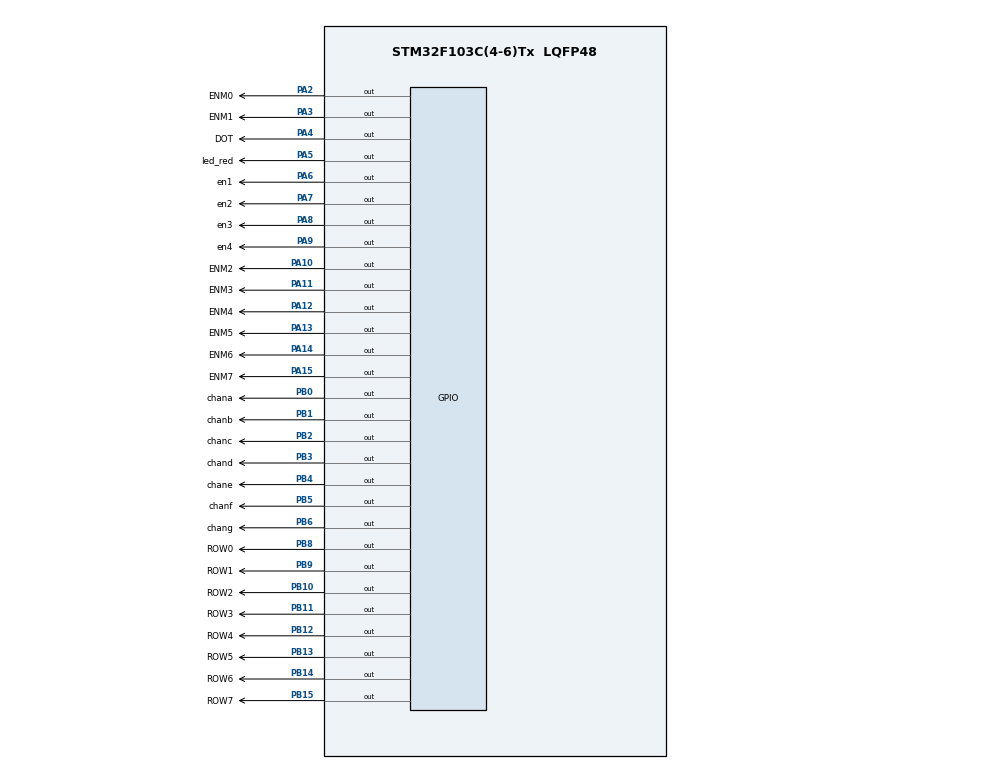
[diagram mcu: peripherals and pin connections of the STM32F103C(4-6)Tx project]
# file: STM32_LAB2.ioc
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Mcu.Family=STM32F1
Mcu.Name=STM32F103C(4-6)Tx
Mcu.Package=LQFP48
NVIC.PriorityGroup=NVIC_PRIORITYGROUP_4
NVIC.TIM2_IRQn=true\:0\:0\:false\:false\:true\:true\:true\:true
PA10.GPIO_Label=ENM2
PA10.Signal=GPIO_Output
PA11.GPIO_Label=ENM3
PA11.Signal=GPIO_Output
PA12.GPIO_Label=ENM4
PA12.Signal=GPIO_Output
PA13.GPIO_Label=ENM5
PA13.Signal=GPIO_Output
PA14.GPIO_Label=ENM6
PA14.Signal=GPIO_Output
PA15.GPIO_Label=ENM7
PA15.Signal=GPIO_Output
PA2.GPIO_Label=ENM0
PA2.Signal=GPIO_Output
PA3.GPIO_Label=ENM1
PA3.Signal=GPIO_Output
PA4.GPIO_Label=DOT
PA4.Signal=GPIO_Output
PA5.GPIO_Label=led_red
PA5.Signal=GPIO_Output
PA6.GPIO_Label=en1
PA6.Signal=GPIO_Output
PA7.GPIO_Label=en2
PA7.Signal=GPIO_Output
PA8.GPIO_Label=en3
PA8.Signal=GPIO_Output
PA9.GPIO_Label=en4
PA9.Signal=GPIO_Output
PB0.GPIO_Label=chana
PB0.Signal=GPIO_Output
PB1.GPIO_Label=chanb
PB1.Signal=GPIO_Output
PB10.GPIO_Label=ROW2
PB10.Signal=GPIO_Output
PB11.GPIO_Label=ROW3
PB11.Signal=GPIO_Output
PB12.GPIO_Label=ROW4
PB12.Signal=GPIO_Output
PB13.GPIO_Label=ROW5
PB13.Signal=GPIO_Output
PB14.GPIO_Label=ROW6
PB14.Signal=GPIO_Output
PB15.GPIO_Label=ROW7
PB15.Signal=GPIO_Output
PB2.GPIO_Label=chanc
PB2.Signal=GPIO_Output
PB3.GPIO_Label=chand
PB3.Signal=GPIO_Output
PB4.GPIO_Label=chane
PB4.Signal=GPIO_Output
PB5.GPIO_Label=chanf
PB5.Signal=GPIO_Output
PB6.GPIO_Label=chang
PB6.Signal=GPIO_Output
PB8.GPIO_Label=ROW0
PB8.Signal=GPIO_Output
PB9.GPIO_Label=ROW1
PB9.Signal=GPIO_Output
ProjectManager.HeapSize=0x200
ProjectManager.StackSize=0x400
ProjectManager.TargetToolchain=STM32CubeIDE
RCC.APB1Freq_Value=8000000
RCC.APB2Freq_Value=8000000
TIM2.Period=9
TIM2.Prescaler=7999
VP_TIM2_VS_ClockSourceINT.Mode=Internal
board=custom

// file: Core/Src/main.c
/* USER CODE BEGIN Header */
/**
  ******************************************************************************
  * @file           : main.c
  * @brief          : Main program body
  ******************************************************************************
  * @attention
  *
  * Copyright (c) 2023 STMicroelectronics.
  * All rights reserved.
  *
  * This software is licensed under terms that can be found in the LICENSE file
  * in the root directory of this software component.
  * If no LICENSE file comes with this software, it is provided AS-IS.
  *
  ******************************************************************************
  */
/* USER CODE END Header */
#include "main.h"

/* USER CODE BEGIN Includes */
#include "software_timer.h"
/* USER CODE END Includes */

TIM_HandleTypeDef htim2;

void SystemClock_Config(void);
static void MX_GPIO_Init(void);
static void MX_TIM2_Init(void);

int main(void)
{

  /* MCU Configuration--------------------------------------------------------*/

  /* Reset of all peripherals, Initializes the Flash interface and the Systick. */
  HAL_Init();

  /* Configure the system clock */
  SystemClock_Config();

  /* Initialize all configured peripherals */
  MX_GPIO_Init();
  MX_TIM2_Init();
  /* USER CODE BEGIN 2 */
  HAL_TIM_Base_Start_IT(&htim2);
  /* USER CODE END 2 */

  /* Infinite loop */
  /* USER CODE BEGIN WHILE */
  const int MAX_LED_MATRIX = 8;
  int index_led_matrix = 0;
  uint8_t matrix_buffer[8] = {0x01, 0x02, 0x03, 0x04, 0x05, 0x06, 0x07, 0x08};

  void updateLEDMatrix(int index) {
      switch (index) {
          case 0:
              // Define the pattern for displaying "A" at index 0
              matrix_buffer[0] = 0b00111100;
              matrix_buffer[1] = 0b01100110;
              matrix_buffer[2] = 0b11000011;
              matrix_buffer[3] = 0b11000011;
              matrix_buffer[4] = 0b11111111;
              matrix_buffer[5] = 0b11000011;
              matrix_buffer[6] = 0b11000011;
              matrix_buffer[7] = 0b00000000;
              break;
          // Define patterns for other indices if needed

          default:
              // Default case, clear the matrix_buffer
              for (int i = 0; i < MAX_LED_MATRIX; i++) {
                  matrix_buffer[i] = 0x00;
              }
              break;
      }
  }

  void display7SEG(int n)
   {
   	switch (n)
   	{
   	case 0 :
   		HAL_GPIO_WritePin(chana_GPIO_Port,chana_Pin, RESET);
   		HAL_GPIO_WritePin(chanb_GPIO_Port,chanb_Pin, RESET);
   		HAL_GPIO_WritePin(chanc_GPIO_Port,chanc_Pin, RESET);
   		HAL_GPIO_WritePin(chand_GPIO_Port,chand_Pin, RESET);
   		HAL_GPIO_WritePin(chane_GPIO_Port,chane_Pin, RESET);
   		HAL_GPIO_WritePin(chanf_GPIO_Port,chanf_Pin, RESET);
   		HAL_GPIO_WritePin(chang_GPIO_Port,chang_Pin, SET);
   	    break ;
   	case 1 :
   		HAL_GPIO_WritePin(chana_GPIO_Port,chana_Pin, SET);
   		HAL_GPIO_WritePin(chanb_GPIO_Port,chanb_Pin, RESET);
   		HAL_GPIO_WritePin(chanc_GPIO_Port,chanc_Pin, RESET);
   		HAL_GPIO_WritePin(chand_GPIO_Port,chand_Pin, SET);
   		HAL_GPIO_WritePin(chane_GPIO_Port,chane_Pin, SET);
   		HAL_GPIO_WritePin(chanf_GPIO_Port,chanf_Pin, SET);
   		HAL_GPIO_WritePin(chang_GPIO_Port,chang_Pin, SET);
   	    break;
   	case 2 :
   		HAL_GPIO_WritePin(chana_GPIO_Port,chana_Pin, RESET);
   		HAL_GPIO_WritePin(chanb_GPIO_Port,chanb_Pin, RESET);
   		HAL_GPIO_WritePin(chanc_GPIO_Port,chanc_Pin, SET);
   		HAL_GPIO_WritePin(chand_GPIO_Port,chand_Pin, RESET);
   		HAL_GPIO_WritePin(chane_GPIO_Port,chane_Pin, RESET);
   		HAL_GPIO_WritePin(chanf_GPIO_Port,chanf_Pin, SET);
   		HAL_GPIO_WritePin(chang_GPIO_Port,chang_Pin, RESET);
   	    break ;
   	case 3 :
   		HAL_GPIO_WritePin(chana_GPIO_Port,chana_Pin, RESET);
   		HAL_GPIO_WritePin(chanb_GPIO_Port,chanb_Pin, RESET);
   		HAL_GPIO_WritePin(chanc_GPIO_Port,chanc_Pin, RESET);
   		HAL_GPIO_WritePin(chand_GPIO_Port,chand_Pin, RESET);
   		HAL_GPIO_WritePin(chane_GPIO_Port,chane_Pin, SET);
   		HAL_GPIO_WritePin(chanf_GPIO_Port,chanf_Pin, SET);
   		HAL_GPIO_WritePin(chang_GPIO_Port,chang_Pin, RESET);
   	    break ;
   	case 4 :
   		HAL_GPIO_WritePin(chana_GPIO_Port,chana_Pin, SET);
   		HAL_GPIO_WritePin(chanb_GPIO_Port,chanb_Pin, RESET);
   		HAL_GPIO_WritePin(chanc_GPIO_Port,chanc_Pin, RESET);
   		HAL_GPIO_WritePin(chand_GPIO_Port,chand_Pin, SET);
   		HAL_GPIO_WritePin(chane_GPIO_Port,chane_Pin, SET);
   		HAL_GPIO_WritePin(chanf_GPIO_Port,chanf_Pin, RESET);
   		HAL_GPIO_WritePin(chang_GPIO_Port,chang_Pin, RESET);
   		break ;
   	case 5 :
   		HAL_GPIO_WritePin(chana_GPIO_Port,chana_Pin, RESET);
   		HAL_GPIO_WritePin(chanb_GPIO_Port,chanb_Pin, SET);
   		HAL_GPIO_WritePin(chanc_GPIO_Port,chanc_Pin, RESET);
   		HAL_GPIO_WritePin(chand_GPIO_Port,chand_Pin, RESET);
   		HAL_GPIO_WritePin(chane_GPIO_Port,chane_Pin, SET);
   		HAL_GPIO_WritePin(chanf_GPIO_Port,chanf_Pin, RESET);
   		HAL_GPIO_WritePin(chang_GPIO_Port,chang_Pin, RESET);
   		break ;
   	case 6 :
   		HAL_GPIO_WritePin(chana_GPIO_Port,chana_Pin, RESET);
   		HAL_GPIO_WritePin(chanb_GPIO_Port,chanb_Pin, SET);
   		HAL_GPIO_WritePin(chanc_GPIO_Port,chanc_Pin, RESET);
   		HAL_GPIO_WritePin(chand_GPIO_Port,chand_Pin, RESET);
   		HAL_GPIO_WritePin(chane_GPIO_Port,chane_Pin, RESET);
   		HAL_GPIO_WritePin(chanf_GPIO_Port,chanf_Pin, RESET);
   		HAL_GPIO_WritePin(chang_GPIO_Port,chang_Pin, RESET);
   	    break ;
   	case 7 :
   		HAL_GPIO_WritePin(chana_GPIO_Port,chana_Pin, RESET);
   		HAL_GPIO_WritePin(chanb_GPIO_Port,chanb_Pin, RESET);
   		HAL_GPIO_WritePin(chanc_GPIO_Port,chanc_Pin, RESET);
   		HAL_GPIO_WritePin(chand_GPIO_Port,chand_Pin, SET);
   		HAL_GPIO_WritePin(chane_GPIO_Port,chane_Pin, SET);
   		HAL_GPIO_WritePin(chanf_GPIO_Port,chanf_Pin, SET);
   		HAL_GPIO_WritePin(chang_GPIO_Port,chang_Pin, SET);
   		break ;
   	case 8 :
   		HAL_GPIO_WritePin(chana_GPIO_Port,chana_Pin, RESET);
   	    HAL_GPIO_WritePin(chanb_GPIO_Port,chanb_Pin, RESET);
   		HAL_GPIO_WritePin(chanc_GPIO_Port,chanc_Pin, RESET);
   		HAL_GPIO_WritePin(chand_GPIO_Port,chand_Pin, RESET);
   		HAL_GPIO_WritePin(chane_GPIO_Port,chane_Pin, RESET);
   		HAL_GPIO_WritePin(chanf_GPIO_Port,chanf_Pin, RESET);
   		HAL_GPIO_WritePin(chang_GPIO_Port,chang_Pin, RESET);
   		break ;
   	case 9 :
   		HAL_GPIO_WritePin(chana_GPIO_Port,chana_Pin, RESET);
   		HAL_GPIO_WritePin(chanb_GPIO_Port,chanb_Pin, RESET);
   		HAL_GPIO_WritePin(chanc_GPIO_Port,chanc_Pin, RESET);
   		HAL_GPIO_WritePin(chand_GPIO_Port,chand_Pin, RESET);
   		HAL_GPIO_WritePin(chane_GPIO_Port,chane_Pin, SET);
   		HAL_GPIO_WritePin(chanf_GPIO_Port,chanf_Pin, RESET);
   		HAL_GPIO_WritePin(chang_GPIO_Port,chang_Pin, RESET);
   		break ;

   	}
   }
  void update7SEG (int index )
  {
  switch ( index )
  {
  case 0:
	  HAL_GPIO_WritePin(en1_GPIO_Port,en1_Pin, RESET);
	  HAL_GPIO_WritePin(en2_GPIO_Port,en2_Pin, SET);
	  HAL_GPIO_WritePin(en3_GPIO_Port,en3_Pin, SET);
	  HAL_GPIO_WritePin(en4_GPIO_Port,en4_Pin, SET);
  break ;
  case 1:
	  HAL_GPIO_WritePin(en1_GPIO_Port,en1_Pin, SET);
	  HAL_GPIO_WritePin(en2_GPIO_Port,en2_Pin, RESET);
	  HAL_GPIO_WritePin(en3_GPIO_Port,en3_Pin, SET);
	  HAL_GPIO_WritePin(en4_GPIO_Port,en4_Pin, SET);
  break ;
  case 2:
	  HAL_GPIO_WritePin(en1_GPIO_Port,en1_Pin, SET);
	  HAL_GPIO_WritePin(en2_GPIO_Port,en2_Pin, SET);
	  HAL_GPIO_WritePin(en3_GPIO_Port,en3_Pin, RESET);
	  HAL_GPIO_WritePin(en4_GPIO_Port,en4_Pin, SET);
  break ;
  case 3:
	  HAL_GPIO_WritePin(en1_GPIO_Port,en1_Pin, SET);
	  HAL_GPIO_WritePin(en2_GPIO_Port,en2_Pin, SET);
	  HAL_GPIO_WritePin(en3_GPIO_Port,en3_Pin, SET);
	  HAL_GPIO_WritePin(en4_GPIO_Port,en4_Pin, RESET);
  break ;
  default :
  break ;
  }
  }
  int index_led;
  int led_buffer[4] = {1 , 2 , 3 , 4};
   const int MAX_LED=4;
   int hour = 15 , minute = 8 , second = 50;
   void updateClockBuffer ()
    {

  	  int hour_tens = hour / 10;
  	  int hour_ones = hour % 10;
  	  int minute_tens = minute / 10;
  	  int minute_ones = minute % 10;

  	  led_buffer[0] = hour_tens;
  	  led_buffer[1] = hour_ones;
  	  led_buffer[2] = minute_tens;
  	  led_buffer[3] = minute_ones;
    }

   settimer1(25);
   settimer2(100);
   settimer3(25);
  while (1)
  {
	  if(timer1_flag == 1)
	  {
	 		  settimer1(25);
	 		  if(index_led + 1 <= MAX_LED) {
	 		  HAL_GPIO_TogglePin(led_red_GPIO_Port, led_red_Pin);
	 		  update7SEG(index_led);
	 		  display7SEG(led_buffer[index_led]);
	 		  index_led++;
	 		  }
	 		  if(index_led + 1 > MAX_LED) {
	 			  index_led = 0;
	 		  }
	 	  }
	 	  if(timer2_flag == 1)
	 	  {
	 		  settimer2(100);
	 		  HAL_GPIO_TogglePin(DOT_GPIO_Port, DOT_Pin);
	 		  second++;
	 		  if(second >= 60)
	 		  {
	 			  second = 0;
	 			  minute++;
	 		  }
	 		  if(minute >= 60)
	 		  {
	 			  minute = 0;
	 			  hour++;
	 		  }
	 		  if(hour >= 24)
	 		  {
	 			  hour = 0;
	 		  }
	 		  updateClockBuffer();

	 	  }
	  if(timer3_flag == 1)
	  {
	   settimer3(25);
	 		  if(index_led_matrix + 1 <= MAX_LED_MATRIX) {
	 			  updateLEDMatrix(index_led_matrix);
	 			  index_led_matrix++;
	 		  }
	 		  if(index_led_matrix + 1> MAX_LED_MATRIX)
	 		  {
	 			  index_led_matrix = 0;
	 		  }
	  }
  }
  /* USER CODE END 3 */
}

void SystemClock_Config(void)
{
  RCC_OscInitTypeDef RCC_OscInitStruct = {0};
  RCC_ClkInitTypeDef RCC_ClkInitStruct = {0};

  /** Initializes the RCC Oscillators according to the specified parameters
  * in the RCC_OscInitTypeDef structure.
  */
  RCC_OscInitStruct.OscillatorType = RCC_OSCILLATORTYPE_HSI;
  RCC_OscInitStruct.HSIState = RCC_HSI_ON;
  RCC_OscInitStruct.HSICalibrationValue = RCC_HSICALIBRATION_DEFAULT;
  RCC_OscInitStruct.PLL.PLLState = RCC_PLL_NONE;
  if (HAL_RCC_OscConfig(&RCC_OscInitStruct) != HAL_OK)
  {
    Error_Handler();
  }

  /** Initializes the CPU, AHB and APB buses clocks
  */
  RCC_ClkInitStruct.ClockType = RCC_CLOCKTYPE_HCLK|RCC_CLOCKTYPE_SYSCLK
                              |RCC_CLOCKTYPE_PCLK1|RCC_CLOCKTYPE_PCLK2;
  RCC_ClkInitStruct.SYSCLKSource = RCC_SYSCLKSOURCE_HSI;
  RCC_ClkInitStruct.AHBCLKDivider = RCC_SYSCLK_DIV1;
  RCC_ClkInitStruct.APB1CLKDivider = RCC_HCLK_DIV1;
  RCC_ClkInitStruct.APB2CLKDivider = RCC_HCLK_DIV1;

  if (HAL_RCC_ClockConfig(&RCC_ClkInitStruct, FLASH_LATENCY_0) != HAL_OK)
  {
    Error_Handler();
  }
}

static void MX_TIM2_Init(void)
{

  TIM_ClockConfigTypeDef sClockSourceConfig = {0};
  TIM_MasterConfigTypeDef sMasterConfig = {0};

  htim2.Instance = TIM2;
  htim2.Init.Prescaler = 7999;
  htim2.Init.CounterMode = TIM_COUNTERMODE_UP;
  htim2.Init.Period = 9;
  htim2.Init.ClockDivision = TIM_CLOCKDIVISION_DIV1;
  htim2.Init.AutoReloadPreload = TIM_AUTORELOAD_PRELOAD_DISABLE;
  if (HAL_TIM_Base_Init(&htim2) != HAL_OK)
  {
    Error_Handler();
  }
  sClockSourceConfig.ClockSource = TIM_CLOCKSOURCE_INTERNAL;
  if (HAL_TIM_ConfigClockSource(&htim2, &sClockSourceConfig) != HAL_OK)
  {
    Error_Handler();
  }
  sMasterConfig.MasterOutputTrigger = TIM_TRGO_RESET;
  sMasterConfig.MasterSlaveMode = TIM_MASTERSLAVEMODE_DISABLE;
  if (HAL_TIMEx_MasterConfigSynchronization(&htim2, &sMasterConfig) != HAL_OK)
  {
    Error_Handler();
  }

}

static void MX_GPIO_Init(void)
{
  GPIO_InitTypeDef GPIO_InitStruct = {0};

  /* GPIO Ports Clock Enable */
  __HAL_RCC_GPIOA_CLK_ENABLE();
  __HAL_RCC_GPIOB_CLK_ENABLE();

  /*Configure GPIO pin Output Level */
  HAL_GPIO_WritePin(GPIOA, DOT_Pin|led_red_Pin|en1_Pin|en2_Pin
                          |en3_Pin|en4_Pin, GPIO_PIN_RESET);

  /*Configure GPIO pin Output Level */
  HAL_GPIO_WritePin(GPIOB, chana_Pin|chanb_Pin|chanc_Pin|chand_Pin
                          |chane_Pin|chanf_Pin|chang_Pin, GPIO_PIN_RESET);

  /*Configure GPIO pins : DOT_Pin led_red_Pin en1_Pin en2_Pin
                           en3_Pin en4_Pin */
  GPIO_InitStruct.Pin = DOT_Pin|led_red_Pin|en1_Pin|en2_Pin
                          |en3_Pin|en4_Pin;
  GPIO_InitStruct.Mode = GPIO_MODE_OUTPUT_PP;
  GPIO_InitStruct.Pull = GPIO_NOPULL;
  GPIO_InitStruct.Speed = GPIO_SPEED_FREQ_LOW;
  HAL_GPIO_Init(GPIOA, &GPIO_InitStruct);

  /*Configure GPIO pins : chana_Pin chanb_Pin chanc_Pin chand_Pin
                           chane_Pin chanf_Pin chang_Pin */
  GPIO_InitStruct.Pin = chana_Pin|chanb_Pin|chanc_Pin|chand_Pin
                          |chane_Pin|chanf_Pin|chang_Pin;
  GPIO_InitStruct.Mode = GPIO_MODE_OUTPUT_PP;
  GPIO_InitStruct.Pull = GPIO_NOPULL;
  GPIO_InitStruct.Speed = GPIO_SPEED_FREQ_LOW;
  HAL_GPIO_Init(GPIOB, &GPIO_InitStruct);

}

/* USER CODE BEGIN 4 */
void HAL_TIM_PeriodElapsedCallback(TIM_HandleTypeDef *htim)
{
	timerrun();
}
/* USER CODE END 4 */

void Error_Handler(void)
{
  __disable_irq();
  while (1)
  {
  }
}
